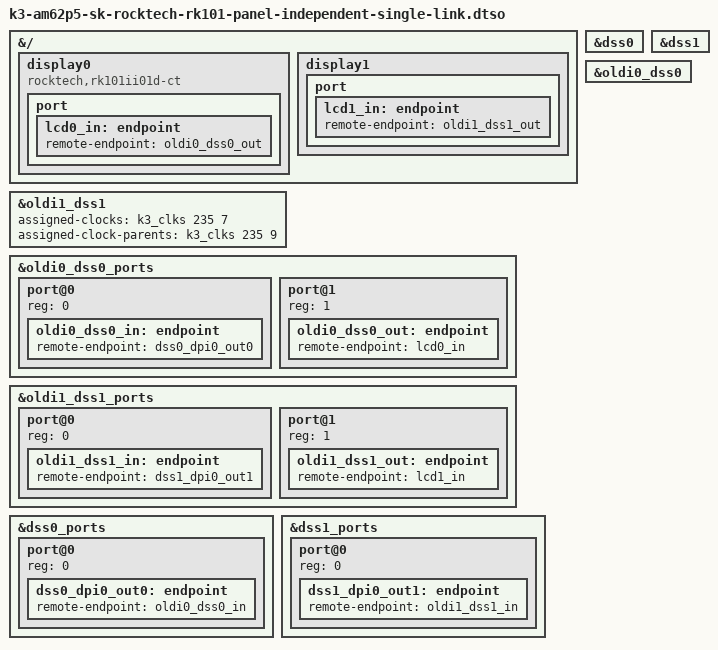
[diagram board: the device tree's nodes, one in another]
// SPDX-License-Identifier: GPL-2.0-or-later OR MIT
/**
 *
 * Copyright (C) 2024 Texas Instruments Incorporated - http://www.ti.com/
 */

/dts-v1/;
/plugin/;

#include <dt-bindings/gpio/gpio.h>
#include <dt-bindings/interrupt-controller/irq.h>

&{/} {
	display0 {
		compatible = "rocktech,rk101ii01d-ct", "panel-simple";

		port {
			lcd0_in: endpoint {
				remote-endpoint = <&oldi0_dss0_out>;
			};
		};
	};

	display1 {
		port {
			lcd1_in: endpoint {
				remote-endpoint = <&oldi1_dss1_out>;
			};
		};
	};
};

&dss0 {
	status = "okay";
};

&dss1 {
	status = "okay";
};

&oldi0_dss0 {
	status = "okay";
};

&oldi1_dss1 {
	status = "okay";

	/*
	 * Set clock parent for OLDI1 so that PLL 18 is
	 * going to OLDI1. By default it is PLL 16.
	 */
	assigned-clocks = <&k3_clks 235 7>;
	assigned-clock-parents = <&k3_clks 235 9>;
};

&oldi0_dss0_ports {
	#address-cells = <1>;
	#size-cells = <0>;

	port@0 {
		reg = <0>;

		oldi0_dss0_in: endpoint {
			remote-endpoint = <&dss0_dpi0_out0>;
		};
	};

	port@1 {
		reg = <1>;

		oldi0_dss0_out: endpoint {
			remote-endpoint = <&lcd0_in>;
		};
	};
};

&oldi1_dss1_ports {
	#address-cells = <1>;
	#size-cells = <0>;

	port@0 {
		reg = <0>;

		oldi1_dss1_in: endpoint {
			remote-endpoint = <&dss1_dpi0_out1>;
		};
	};

	port@1 {
		reg = <1>;

		oldi1_dss1_out: endpoint {
			remote-endpoint = <&lcd1_in>;
		};
	};
};

&dss0_ports {
	#address-cells = <1>;
	#size-cells = <0>;

	/* DSS0 VP1: Output to OLDI0 */
	port@0 {
		reg = <0>;

		dss0_dpi0_out0: endpoint {
			remote-endpoint = <&oldi0_dss0_in>;
		};
	};
};

&dss1_ports {
	#address-cells = <1>;
	#size-cells = <0>;

	/* DSS1 VP1: Output to OLDI1 */
	port@0 {
		reg = <0>;

		dss1_dpi0_out1: endpoint {
			remote-endpoint = <&oldi1_dss1_in>;
		};
	};
};

